# R7FA6T1 register map
Vendor: Renesas; Series: RA6; File version: 1.2
CPU: CM4 r0p1, little endian, MPU, FPU, VTOR, 4 interrupt priority bits
Registers are 8-bit, read-write, reset 0x0 unless marked. A register's access mark holds for its fields unless they carry their own. Offsets are from the block's base; [hi:lo] are bit positions; {n}, {i} and the like mark numbered series.

## TSN — Temperature Sensor
Base 0x4005D000
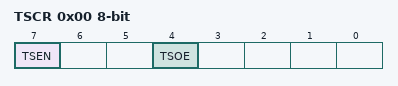
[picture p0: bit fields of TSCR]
0x00 TSCR — Temperature Sensor Control Register
  [7] TSEN — Temperature Sensor Output Enable
    0=Stops the temperature sensor; 1=Starts the temperature sensor
  [4] TSOE — Temperature Sensor Enable
    0=Disables output from the temperature sensor to the 12-bit A/D converter; 1=Enables output from the temperature sensor to the 12-bit A/D converter

## DAC12 — 12-bit D/A converter
Base 0x4005E000
{0x0+2i} DADR{i} (i=0..1) 16-bit — D/A Data Register {i}
  [15:0] DADR — D/A Data RegisterNOTE: When DADPR.DPSEL = 0, the high-order 4 bits are fixed to 0: right justified format. When DADPR.DPSEL = 1, the low-order 4 bits are fixed to 0: left justified format.
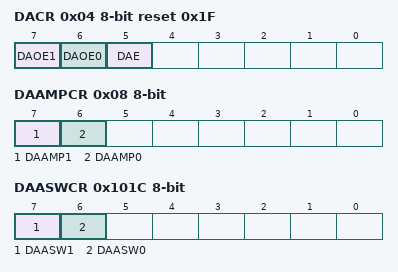
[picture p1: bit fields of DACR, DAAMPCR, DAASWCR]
0x04 DACR reset 0x1F — D/A Control Register
  [7] DAOE1 — D/A Output Enable 1
    0=Analog output of channel 1 (DA1) is disabled; 1=D/A conversion of channel 1 is enabled. Analog output of channel 1 (DA1) is enabled.
  [6] DAOE0 — D/A Output Enable 0
    0=Analog output of channel 0 (DA0) is disabled; 1=D/A conversion of channel 0 is enabled. Analog output of channel 0 (DA0) is enabled.
  [5] DAE — D/A Enable
    0=D/A conversion is independently controlled on channels 0 and 1; 1=D/A conversion on channels 0 and 1 is controlled as a single whole
0x05 DADPR — DADRm Format Select Register
  [7] DPSEL — DADRm Format Select
    0=Right justified format; 1=Left justified format
0x06 DAADSCR — D/A-A/D Synchronous Start Control Register
  [7] DAADST — D/A-A/D Synchronous Conversion
    0=D/A converter operation does not synchronize with A/D converter operation (unit 1) (countermeasure against interference between D/A and A/D conversions is disabled); 1=D/A converter operation synchronizes with A/D converter operation (unit 1) (countermeasure against interference between D/A and A/D conversions is enabled)
0x08 DAAMPCR — D/A Output Amplifier Control Register
  [7] DAAMP1 — Amplifier Control 1
    0=Output amplifier of channel 1 is not used; 1=Output amplifier of channel 1 is used
  [6] DAAMP0 — Amplifier Control 0
    0=Output amplifier of channel 0 is not used; 1=Output amplifier of channel 0 is used
0x101C DAASWCR — D/A Amplifier Stabilization Wait Control Register
  [7] DAASW1 — D/A Amplifier Stabilization Wait 1
    0=Amplifier stabilization wait off (output) for channel 1; 1=Amplifier stabilization wait on (high-Z) for channel 1
  [6] DAASW0 — D/A Amplifier Stabilization Wait 0
    0=Amplifier stabilization wait off (output) for channel 0; 1=Amplifier stabilization wait on (high-Z) for channel 0
0x10C0 DAADUSR — D/A A/D Synchronous Unit Select Register
  [1] AMADSEL1 — A/D Unit 1 Select
    0=Unit 1 is not selected; 1=Unit 1 is selected

## IRDA — Infrared Data Association
Base 0x40070F00
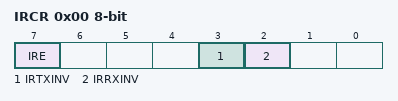
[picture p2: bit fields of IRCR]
0x00 IRCR — IrDA Control Register
  [7] IRE — IrDA Enable
    0=Serial I/O pins are used for normal serial communication; 1=Serial I/O pins are used for IrDA data communication
  [3] IRTXINV — IRTXD Polarity Switching
    0=Data to be transmitted is output to IRTXD as is; 1=Data to be transmitted is output to IRTXD after the polarity is inverted
  [2] IRRXINV — IRRXD Polarity Switching
    0=IRRXD input is used as received data as is; 1=IRRXD input is used as received data after the polarity is inverted

## CRC — CRC Calculator
Base 0x40074000
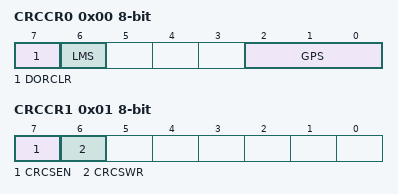
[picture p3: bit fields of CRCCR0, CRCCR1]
0x00 CRCCR0 — CRC Control Register0
  [7] DORCLR wo — CRCDOR Register Clear
    0=No effect; 1=Clears the CRCDOR register
  [6] LMS — CRC Calculation Switching
    0=Generates CRC for LSB first communication; 1=Generates CRC for MSB first communication
  [2:0] GPS — CRC Generating Polynomial Switching
    0=No calculation is executed; 1=8-bit CRC-8 (X8 + X2 + X + 1); 2=16-bit CRC-16 (X16 + X15 + X2 + 1); 3=16-bit CRC-CCITT (X16 + X12 + X5 + 1); 4=32-bit CRC-32 (X32+X26+X23+X22+X16+X12+X11+X10+X8+X7+X5+X4+X2+X+1); 5=32-bit CRC-32C (X32+X28+X27+X26+ X25+X23+X22+X20+X19+X18+X14+X13+X11+X10+X9+X8+X6+1); other=others (No calculation is executed.)
0x01 CRCCR1 — CRC Control Register1
  [7] CRCSEN — Snoop enable bit
    0=Disabled; 1=Enabled
  [6] CRCSWR — Snoop-on-write/read switch bit
    0=Snoop-on-read; 1=Snoop-on-write
0x04 CRCDIR 32-bit — CRC Data Input Register
  [31:0] CRCDIR — Calculation input Data (Case of CRC-32, CRC-32C )
0x04 CRCDIR_BY (alternate view of CRCDIR) — CRC Data Input Register (byte access)
  [7:0] CRCDIR_BY — Calculation input Data ( Case of CRC-8, CRC-16 or CRC-CCITT )
0x08 CRCDOR 32-bit — CRC Data Output Register
  [31:0] CRCDOR — Calculation output Data (Case of CRC-32, CRC-32C )
0x08 CRCDOR_HA 16-bit (alternate view of CRCDOR) — CRC Data Output Register (halfword access)
  [15:0] CRCDOR_HA — Calculation output Data (Case of CRC-16 or CRC-CCITT )
0x08 CRCDOR_BY (alternate view of CRCDOR) — CRC Data Output Register(byte access)
  [7:0] CRCDOR_BY — Calculation output Data (Case of CRC-8 )
0x0C CRCSAR 16-bit — Snoop Address Register
  [13:0] CRCSA — snoop address bitSet the I/O register address to snoop
    3=SCI0.TDR; 5=SCI0.RDR; 35=SCI1.TDR; 37=SCI1.RDR; 67=SCI2.TDR; 69=SCI2.RDR; 99=SCI3.TDR; 101=SCI3.RDR; 131=SCI4.TDR; 133=SCI4.RDR; 163=SCI5.TDR; 165=SCI5.RDR; 195=SCI6.TDR; 197=SCI6.RDR; 227=SCI7.TDR; 229=SCI7.RDR; 0x103=SCI8.TDR; 0x105=SCI8.RDR; 0x123=SCI9.TDR; 0x125=SCI9.RDR; other=others (Settings other than above are prohibited.)
